# MCU_MSRAM_1MB0_MSRAM128KX64E_ECC_AGGR_ECC_AGGR_REGS register map
Vendor: Texas Instruments
Peripheral module from a debugger description file (folder J7_AHP).
Registers are 32-bit, access not given, reset 0x0 unless marked. A register's access mark holds for its fields unless they carry their own. Offsets are as the file gives them; lines under a group give offsets from that group; [hi:lo] are bit positions; {n}, {i} and the like mark numbered series; 'fields as' and 'values as' point back to an identical list; <NAME> marks a mode.

## MCU_MSRAM_1MB0_MSRAM128KX64E_ECC_AGGR_ECC_AGGR_REGS
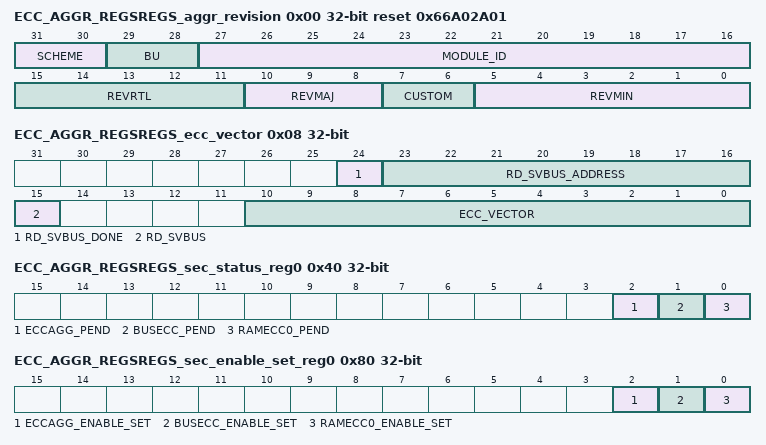
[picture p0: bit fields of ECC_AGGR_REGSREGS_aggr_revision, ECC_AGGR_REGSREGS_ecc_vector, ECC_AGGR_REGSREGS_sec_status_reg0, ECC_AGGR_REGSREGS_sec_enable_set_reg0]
0x00 ECC_AGGR_REGSREGS_aggr_revision ro reset 0x66A02A01
  [31:30] SCHEME
  [29:28] BU
  [27:16] MODULE_ID
  [15:11] REVRTL — RTL version
  [10:8] REVMAJ — Major version
  [7:6] CUSTOM — Custom version
  [5:0] REVMIN — Minor version
0x08 ECC_AGGR_REGSREGS_ecc_vector
  [24] RD_SVBUS_DONE — Status to indicate if read on serial VBUS is complete, write of any value will clear this bit. (access R/W1TC)
  [23:16] RD_SVBUS_ADDRESS rw — Read address
  [15] RD_SVBUS — Write 1 to trigger a read on the serial VBUS (access R/W1TS)
  [10:0] ECC_VECTOR rw — Value written to select the corresponding ECC RAM for control or status
0x0C ECC_AGGR_REGSREGS_misc_status ro reset 0x3
  [10:0] NUM_RAMS — Indicates the number of RAMS serviced by the ECC aggregator
0x10 ECC_AGGR_REGSREGS_reserved_svbus rw
  [31:0] DATA — Serial VBUS register data
0x3C ECC_AGGR_REGSREGS_sec_eoi_reg
  [0] EOI_WR — EOI Register (access R/W1TS)
0x40 ECC_AGGR_REGSREGS_sec_status_reg0
  [2] ECCAGG_PEND — Interrupt Pending Status for eccagg_pend (access R/W1TS)
  [1] BUSECC_PEND — Interrupt Pending Status for busecc_pend (access R/W1TS)
  [0] RAMECC0_PEND — Interrupt Pending Status for ramecc0_pend (access R/W1TS)
0x80 ECC_AGGR_REGSREGS_sec_enable_set_reg0
  [2] ECCAGG_ENABLE_SET — Interrupt Enable Set Register for eccagg_pend (access R/W1TS)
  [1] BUSECC_ENABLE_SET — Interrupt Enable Set Register for busecc_pend (access R/W1TS)
  [0] RAMECC0_ENABLE_SET — Interrupt Enable Set Register for ramecc0_pend (access R/W1TS)
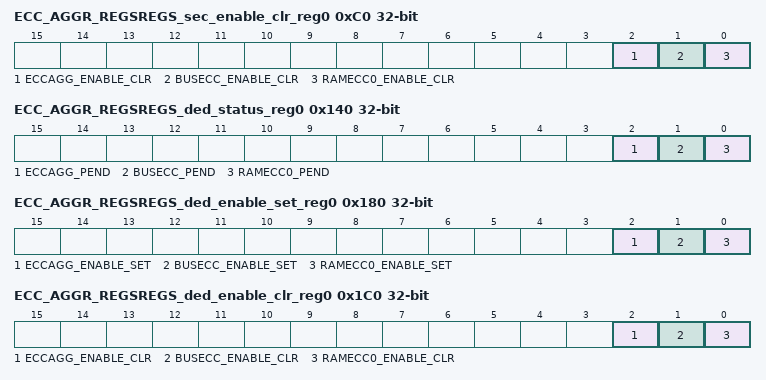
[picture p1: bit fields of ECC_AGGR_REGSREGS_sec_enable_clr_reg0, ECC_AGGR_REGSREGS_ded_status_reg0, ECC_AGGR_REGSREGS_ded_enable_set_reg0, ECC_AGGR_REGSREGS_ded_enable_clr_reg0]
0xC0 ECC_AGGR_REGSREGS_sec_enable_clr_reg0
  [2] ECCAGG_ENABLE_CLR — Interrupt Enable Clear Register for eccagg_pend (access R/W1TC)
  [1] BUSECC_ENABLE_CLR — Interrupt Enable Clear Register for busecc_pend (access R/W1TC)
  [0] RAMECC0_ENABLE_CLR — Interrupt Enable Clear Register for ramecc0_pend (access R/W1TC)
0x13C ECC_AGGR_REGSREGS_ded_eoi_reg
  [0] EOI_WR — EOI Register (access R/W1TS)
0x140 ECC_AGGR_REGSREGS_ded_status_reg0
  fields as ECC_AGGR_REGSREGS_sec_status_reg0
0x180 ECC_AGGR_REGSREGS_ded_enable_set_reg0
  fields as ECC_AGGR_REGSREGS_sec_enable_set_reg0
0x1C0 ECC_AGGR_REGSREGS_ded_enable_clr_reg0
  fields as ECC_AGGR_REGSREGS_sec_enable_clr_reg0
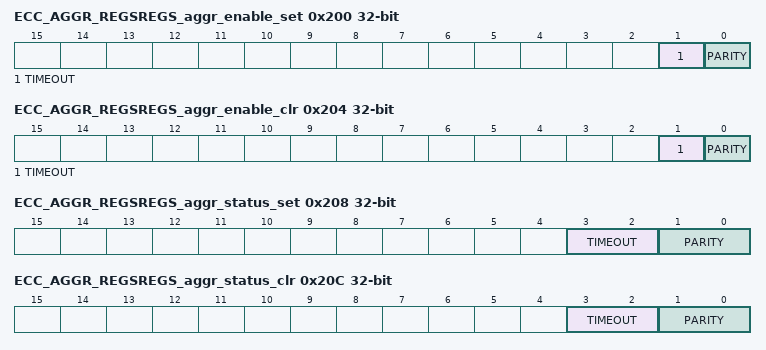
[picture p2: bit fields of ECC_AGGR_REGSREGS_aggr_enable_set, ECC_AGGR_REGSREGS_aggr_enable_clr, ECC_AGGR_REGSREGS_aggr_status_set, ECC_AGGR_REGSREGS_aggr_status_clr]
0x200 ECC_AGGR_REGSREGS_aggr_enable_set
  [1] TIMEOUT — interrupt enable set for svbus timeout errors (access R/W1TS)
  [0] PARITY — interrupt enable set for parity errors (access R/W1TS)
0x204 ECC_AGGR_REGSREGS_aggr_enable_clr
  [1] TIMEOUT — interrupt enable clear for svbus timeout errors (access R/W1TC)
  [0] PARITY — interrupt enable clear for parity errors (access R/W1TC)
0x208 ECC_AGGR_REGSREGS_aggr_status_set
  [3:2] TIMEOUT — interrupt status set for svbus timeout errors (access R/WI)
  [1:0] PARITY — interrupt status set for parity errors (access R/WI)
0x20C ECC_AGGR_REGSREGS_aggr_status_clr
  [3:2] TIMEOUT — interrupt status clear for svbus timeout errors (access R/WD)
  [1:0] PARITY — interrupt status clear for parity errors (access R/WD)
